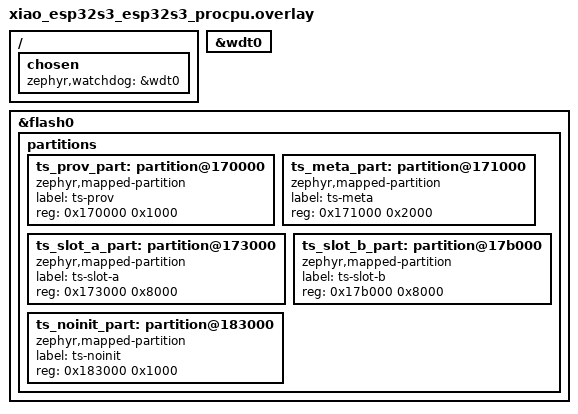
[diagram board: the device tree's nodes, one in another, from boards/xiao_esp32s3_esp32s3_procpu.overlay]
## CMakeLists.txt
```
# SPDX-License-Identifier: Apache-2.0
cmake_minimum_required(VERSION 3.20.0)
find_package(Zephyr REQUIRED HINTS $ENV{ZEPHYR_BASE})
project(wdtbench)

target_sources(app PRIVATE src/main.c)
```

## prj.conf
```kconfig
# SPDX-License-Identifier: Apache-2.0
# wdtbench（DEC-48 实施批）：看门狗接线真机验证（无网络面——纯本地链路）。
CONFIG_PRINTK=y
CONFIG_TS_CORE=y
CONFIG_TS_SAFETY=y
CONFIG_TS_HAL=y
CONFIG_TS_STORE=y
CONFIG_TS_APP_WAMR=y
CONFIG_TS_TEST=y
CONFIG_MAIN_STACK_SIZE=8192
CONFIG_MAIN_THREAD_PRIORITY=15

# DEC-48④ L3/L4 真机层：task_wdt 硬件回退（esp32 MWDT）
# 硬 WDT ≈ MIN_TIMEOUT + FALLBACK_DELAY = 10s（对齐 TS_HARD_WDT_CAP_MS）
CONFIG_WATCHDOG=y
CONFIG_TASK_WDT_HW_FALLBACK=y
CONFIG_TASK_WDT_MIN_TIMEOUT=5000
CONFIG_TASK_WDT_HW_FALLBACK_DELAY=5000
```

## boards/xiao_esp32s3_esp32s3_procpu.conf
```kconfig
# wdtbench（DEC-48）：内存形态 = deploybench 减网络面（PSRAM 承 WAMR 堆；
# 无 WiFi/zenoh → 系统堆降档）。
CONFIG_ESP_SPIRAM=y
CONFIG_SPIRAM_MODE_OCT=y
CONFIG_ESP_SPIRAM_MEMTEST=y
CONFIG_TS_APP_PSRAM_HEAP=y
CONFIG_TS_APP_WAMR_HEAP=262144
CONFIG_TS_STORE_SLOT_SIZE=32768
CONFIG_TS_APP_LOAD_MAX=2048
CONFIG_HEAP_MEM_POOL_SIZE=131072

# 验签双区 scratch（DEC-49：小夹具 → 1024）
CONFIG_TS_VERIFY_SCRATCH=1024
# 4.5 复验批（同型防御）：verify 链在 4096 main 栈实测挂死（persistbench
# 实证——教训 31⑤ 同型）；8192 定值。
CONFIG_MAIN_STACK_SIZE=8192
```

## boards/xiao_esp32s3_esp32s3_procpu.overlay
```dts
/*
 * wdtbench（DEC-48）：ts-store flash 五分区（persistbench/deploybench 同款）
 * + esp32s3 硬件看门狗使能（task_wdt 硬件回退经 chosen 接线）。
 */

&wdt0 {
	status = "okay";
};

/ {
	chosen {
		zephyr,watchdog = &wdt0;
	};
};

/delete-node/ &slot1_partition;

&flash0 {
	partitions {
		ts_prov_part: partition@170000 {
			compatible = "zephyr,mapped-partition";
			label = "ts-prov";
			reg = <0x170000 0x1000>;
		};
		ts_meta_part: partition@171000 {
			compatible = "zephyr,mapped-partition";
			label = "ts-meta";
			reg = <0x171000 0x2000>;
		};
		ts_slot_a_part: partition@173000 {
			compatible = "zephyr,mapped-partition";
			label = "ts-slot-a";
			reg = <0x173000 0x8000>;
		};
		ts_slot_b_part: partition@17b000 {
			compatible = "zephyr,mapped-partition";
			label = "ts-slot-b";
			reg = <0x17b000 0x8000>;
		};
		ts_noinit_part: partition@183000 {
			compatible = "zephyr,mapped-partition";
			label = "ts-noinit";
			reg = <0x183000 0x1000>;
		};
	};
};
```

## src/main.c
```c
/* SPDX-License-Identifier: Apache-2.0 */
/* wdtbench（DEC-48 实施批）：看门狗接线真机验证——两阶段。
 * 阶段 B（L1/L2 防线）：装载 tick 死循环 APP（wdt_pkg.h 夹具，机械生成）
 * → 指令配额（TS_APP_INSTR_TICK）超限抛 "instruction limit exceeded"
 * → 宿主健康失败 3 连 → 回滚自停 + 系统存活（APPMGR 源持续喂狗）。
 * 阶段 C（L3 复位闭环）：sysworkq 协作级自旋工作项 → 巡检停喂 →
 * task_wdt 通道过期 → sys_reboot（串口观测重启即判据；该直通路径无
 * noinit 留痕——ISR 上下文不可写 flash，wdt.c 文件头如实登记）。
 * 判据（WB* console 行）：
 *   WB1 install（TEST 语义验签 = 结构检查）
 *   WB2 APP ACTIVE（boot 步骤 8 装载）
 *   WB3 回滚确认（state ≥ ROLLBACK + rollback_count ≥ 1 + 系统存活）
 *   WB PASS → 3s 后 WB4 阶段 C 自旋 → 预期复位（通道 5s） */
#include <string.h>
#include <zephyr/kernel.h>
#include <zephyr/sys/printk.h>
#include <ts/appmgr.h>
#include <ts/core.h>

#include "wdt_pkg.h"

/* TEST 构建根公钥占位（pkg.c fail-closed：真验签未接入前非测试构建拒装） */
static const uint8_t root_pub[32];

static struct k_work spin_work;

static void phase_c_spin(struct k_work *w)
{
	ARG_UNUSED(w);
	for (;;) {
		/* 协作级自旋：饿死 sysworkq（巡检/estop 补发停摆）；ISR 与
		 * k_timer 不受影响 → task_wdt 通道过期 → sys_reboot。 */
	}
}

static void watcher_thread(void *p1, void *p2, void *p3)
{
	ARG_UNUSED(p1);
	ARG_UNUSED(p2);
	ARG_UNUSED(p3);
	ts_app_info_t info;

	/* 等 APP 生命周期推进：tick 死循环 → 配额异常 ×3 → 回滚。
	 * 注：配额终止全程 ~600ms（3×[tick 周期 100ms + 配额上界]），快于
	 * 轮询周期——ACTIVE 瞬态可能错过；判据以终态为准（若配额失效，
	 * tick 永久挂起 → 永不回滚 → 超时 FAIL = 判别器）。 */
	bool rolled = false;
	int last_state = -1;

	for (int i = 0; i < 150; i++) {
		if (ts_appmgr_get_info(&info) == TS_OK) {
			if (info.state != last_state) {
				printk("WB2 state=%d rb=%u running=%d t=%ums\n",
				       (int)info.state, info.rollback_count,
				       (int)ts_appmgr_app_running(),
				       (unsigned)k_uptime_get_32());
				last_state = info.state;
			}
			if (info.state >= TS_APP_ROLLBACK &&
			    info.rollback_count >= 1) {
				rolled = true;
				break;
			}
		}
		k_msleep(100);
	}
	uint32_t t = (uint32_t)k_uptime_get_32();

	if (!rolled) {
		printk("WB FAIL no rollback (state=%d rb=%u running=%d)\n",
		       (int)info.state, info.rollback_count,
		       (int)ts_appmgr_app_running());
		return;
	}
	printk("WB3 rollback state=%d rb=%u running=%d（tick 死循环被配额终止）\n",
	       (int)info.state, info.rollback_count, (int)ts_appmgr_app_running());
	printk("WB PASS 阶段 B：L2 指令配额终止 + L1 系统存活 t=%ums\n", t);

	k_msleep(3000);
	printk("WB4 阶段 C：sysworkq 自旋 → 预期 task_wdt 复位（通道 %ums）\n",
	       CONFIG_TS_WDT_CHANNEL_MS);
	k_work_init(&spin_work, phase_c_spin);
	k_work_submit_to_queue(&k_sys_work_q, &spin_work);
	for (;;) {
		k_sleep(K_SECONDS(10));
		printk("WB alive t=%u（若见此行 = 阶段 C 复位失效）\n",
		       (unsigned)k_uptime_get_32());
	}
}
K_THREAD_DEFINE(wb_tid, 4096, watcher_thread, NULL, NULL, NULL, 5, 0, 0);

int main(void)
{
	printk("WB0 wdtbench（DEC-48：看门狗接线真机验证）\n");

	ts_app_info_t info;
	ts_res_t r = ts_appmgr_install(wdt_pkg, sizeof(wdt_pkg), root_pub, &info);

	printk("WB1 install r=%d state=%d slot=%u app=%s\n",
	       (int)r, (int)info.state, info.active_slot, info.app_id);
	if (r != TS_OK) {
		printk("WB FAIL install\n");
		return 1;
	}
	ts_core_boot(); /* noreturn：步骤 8 装载 APP → 死循环 → 配额 → 回滚 */
	return 0;
}
```

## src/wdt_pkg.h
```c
/* 机械生成（gen_wdt_pkg.sh）——wdt.spin.bench-1.0.0.tsap，593B（v2 + 测试根） */
static const uint8_t wdt_pkg[593] = {
	0x54, 0x53, 0x41, 0x50, 0x00, 0x02, 0x00, 0x00, 0x00, 0x76, 0x00, 0x00,
	0x00, 0x75, 0x00, 0x01, 0x50, 0x9d, 0x49, 0x8f, 0xa6, 0x7d, 0x6d, 0x88,
	0x30, 0x5f, 0x0d, 0x67, 0x83, 0x62, 0xfe, 0xaa, 0x2c, 0xa0, 0x66, 0x90,
	0xad, 0x3a, 0x95, 0xc1, 0x5a, 0x09, 0x3f, 0x36, 0x35, 0x20, 0x6f, 0x15,
	0xa7, 0x64, 0x63, 0x61, 0x70, 0x73, 0x80, 0x66, 0x61, 0x70, 0x70, 0x5f,
	0x69, 0x64, 0x6e, 0x77, 0x64, 0x74, 0x2e, 0x73, 0x70, 0x69, 0x6e, 0x2e,
	0x62, 0x65, 0x6e, 0x63, 0x68, 0x67, 0x61, 0x70, 0x70, 0x5f, 0x76, 0x65,
	0x72, 0x65, 0x31, 0x2e, 0x30, 0x2e, 0x30, 0x67, 0x65, 0x78, 0x70, 0x6f,
	0x72, 0x74, 0x73, 0x83, 0x68, 0x61, 0x70, 0x70, 0x5f, 0x69, 0x6e, 0x69,
	0x74, 0x68, 0x61, 0x70, 0x70, 0x5f, 0x74, 0x69, 0x63, 0x6b, 0x6b, 0x68,
	0x65, 0x61, 0x6c, 0x74, 0x68, 0x5f, 0x70, 0x69, 0x6e, 0x67, 0x67, 0x68,
	0x65, 0x61, 0x70, 0x5f, 0x6b, 0x62, 0x01, 0x68, 0x73, 0x74, 0x61, 0x63,
	0x6b, 0x5f, 0x6b, 0x62, 0x08, 0x6a, 0x6d, 0x69, 0x6e, 0x5f, 0x66, 0x77,
	0x5f, 0x76, 0x65, 0x72, 0x65, 0x31, 0x2e, 0x30, 0x2e, 0x30, 0x00, 0x61,
	0x73, 0x6d, 0x01, 0x00, 0x00, 0x00, 0x01, 0x0a, 0x02, 0x60, 0x00, 0x01,
	0x7f, 0x60, 0x01, 0x7f, 0x01, 0x7f, 0x03, 0x04, 0x03, 0x00, 0x01, 0x00,
	0x04, 0x05, 0x01, 0x70, 0x01, 0x01, 0x01, 0x05, 0x03, 0x01, 0x00, 0x02,
	0x06, 0x08, 0x01, 0x7f, 0x01, 0x41, 0x80, 0x88, 0x04, 0x0b, 0x07, 0x2e,
	0x04, 0x06, 0x6d, 0x65, 0x6d, 0x6f, 0x72, 0x79, 0x02, 0x00, 0x0b, 0x68,
	0x65, 0x61, 0x6c, 0x74, 0x68, 0x5f, 0x70, 0x69, 0x6e, 0x67, 0x00, 0x00,
	0x08, 0x61, 0x70, 0x70, 0x5f, 0x69, 0x6e, 0x69, 0x74, 0x00, 0x01, 0x08,
	0x61, 0x70, 0x70, 0x5f, 0x74, 0x69, 0x63, 0x6b, 0x00, 0x02, 0x0a, 0x13,
	0x03, 0x04, 0x00, 0x41, 0x00, 0x0b, 0x04, 0x00, 0x41, 0x00, 0x0b, 0x07,
	0x00, 0x03, 0x7f, 0x0c, 0x00, 0x0b, 0x0b, 0xd2, 0x84, 0x43, 0xa1, 0x01,
	0x27, 0xa0, 0x58, 0xeb, 0xa7, 0x64, 0x63, 0x61, 0x70, 0x73, 0x80, 0x66,
	0x61, 0x70, 0x70, 0x5f, 0x69, 0x64, 0x6e, 0x77, 0x64, 0x74, 0x2e, 0x73,
	0x70, 0x69, 0x6e, 0x2e, 0x62, 0x65, 0x6e, 0x63, 0x68, 0x67, 0x61, 0x70,
	0x70, 0x5f, 0x76, 0x65, 0x72, 0x65, 0x31, 0x2e, 0x30, 0x2e, 0x30, 0x67,
	0x65, 0x78, 0x70, 0x6f, 0x72, 0x74, 0x73, 0x83, 0x68, 0x61, 0x70, 0x70,
	0x5f, 0x69, 0x6e, 0x69, 0x74, 0x68, 0x61, 0x70, 0x70, 0x5f, 0x74, 0x69,
	0x63, 0x6b, 0x6b, 0x68, 0x65, 0x61, 0x6c, 0x74, 0x68, 0x5f, 0x70, 0x69,
	0x6e, 0x67, 0x67, 0x68, 0x65, 0x61, 0x70, 0x5f, 0x6b, 0x62, 0x01, 0x68,
	0x73, 0x74, 0x61, 0x63, 0x6b, 0x5f, 0x6b, 0x62, 0x08, 0x6a, 0x6d, 0x69,
	0x6e, 0x5f, 0x66, 0x77, 0x5f, 0x76, 0x65, 0x72, 0x65, 0x31, 0x2e, 0x30,
	0x2e, 0x30, 0x00, 0x61, 0x73, 0x6d, 0x01, 0x00, 0x00, 0x00, 0x01, 0x0a,
	0x02, 0x60, 0x00, 0x01, 0x7f, 0x60, 0x01, 0x7f, 0x01, 0x7f, 0x03, 0x04,
	0x03, 0x00, 0x01, 0x00, 0x04, 0x05, 0x01, 0x70, 0x01, 0x01, 0x01, 0x05,
	0x03, 0x01, 0x00, 0x02, 0x06, 0x08, 0x01, 0x7f, 0x01, 0x41, 0x80, 0x88,
	0x04, 0x0b, 0x07, 0x2e, 0x04, 0x06, 0x6d, 0x65, 0x6d, 0x6f, 0x72, 0x79,
	0x02, 0x00, 0x0b, 0x68, 0x65, 0x61, 0x6c, 0x74, 0x68, 0x5f, 0x70, 0x69,
	0x6e, 0x67, 0x00, 0x00, 0x08, 0x61, 0x70, 0x70, 0x5f, 0x69, 0x6e, 0x69,
	0x74, 0x00, 0x01, 0x08, 0x61, 0x70, 0x70, 0x5f, 0x74, 0x69, 0x63, 0x6b,
	0x00, 0x02, 0x0a, 0x13, 0x03, 0x04, 0x00, 0x41, 0x00, 0x0b, 0x04, 0x00,
	0x41, 0x00, 0x0b, 0x07, 0x00, 0x03, 0x7f, 0x0c, 0x00, 0x0b, 0x0b, 0x58,
	0x40, 0xec, 0xbe, 0x5b, 0xd7, 0xf2, 0x16, 0xb7, 0xe8, 0x06, 0x74, 0x78,
	0x6f, 0xc1, 0x35, 0xcb, 0x68, 0xcb, 0x41, 0xa2, 0x9b, 0x86, 0xb7, 0xed,
	0x64, 0x12, 0x62, 0xcb, 0x37, 0x14, 0x8a, 0x9f, 0x32, 0xff, 0x9f, 0xa7,
	0xcd, 0x38, 0x80, 0xb8, 0x02, 0xbd, 0x64, 0xd1, 0x83, 0xb6, 0x7a, 0x60,
	0x8d, 0x49, 0xa4, 0xd7, 0xb9, 0xa6, 0xba, 0xdf, 0x44, 0x5e, 0x01, 0x89,
	0xb1, 0x88, 0x99, 0xf3, 0x00,
};
```
